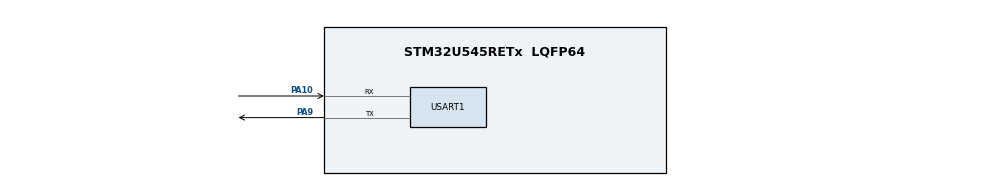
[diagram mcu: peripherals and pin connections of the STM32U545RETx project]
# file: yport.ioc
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CORTEX_M33_NS.userName=CORTEX_M33
Mcu.Family=STM32U5
Mcu.Name=STM32U545RETx
Mcu.Package=LQFP64
NVIC.PriorityGroup=NVIC_PRIORITYGROUP_4
NVIC.TIM6_IRQn=true\:15\:0\:false\:false\:true\:false\:true\:true
NVIC.TimeBase=TIM6_IRQn
NVIC.TimeBaseIP=TIM6
PA10.Mode=Asynchronous
PA10.Signal=USART1_RX
PA9.Mode=Asynchronous
PA9.Signal=USART1_TX
PC14-OSC32_IN\ (PC14).Mode=LSE-External-Oscillator
PC14-OSC32_IN\ (PC14).Signal=RCC_OSC32_IN
PC15-OSC32_OUT\ (PC15).Mode=LSE-External-Oscillator
PC15-OSC32_OUT\ (PC15).Signal=RCC_OSC32_OUT
ProjectManager.HeapSize=0x200
ProjectManager.StackSize=0x400
ProjectManager.TargetToolchain=STM32CubeIDE
RCC.ADCFreq_Value=16000000
RCC.DACCLockSelectionVirtual=RCC_DAC1CLKSOURCE_LSI
RCC.DACCLockSelectionVirtualString=RCC_DAC1CLKSOURCE_LSI
RCC.EPOD_VALUE=4000000
RCC.HSE_VALUE=16000000
RCC.HSI48_VALUE=48000000
RCC.HSI_VALUE=16000000
RCC.LSIDIV_VALUE=32000
RCC.MSI_VALUE=4000000
RCC.USBFreq_Value=48000000
RCC.VCOOutputFreq_Value=516000000
USART1.VirtualMode-Asynchronous=VM_ASYNC
VP_LPBAMQUEUE_VS_QUEUE.Mode=QUEUEMODE
VP_LPBAM_VS_SIG1.Mode=SmartRun
VP_LPBAM_VS_SIG4.Mode=LPDMA1
VP_MEMORYMAP_VS_MEMORYMAP.Mode=CurAppReg
VP_PWR_VS_SECSignals.Mode=Security/Privilege
VP_SYS_VS_tim6.Mode=TIM6
board=custom

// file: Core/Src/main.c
/* USER CODE BEGIN Header */
/**
  ******************************************************************************
  * @file           : main.c
  * @brief          : Main program body
  ******************************************************************************
  * @attention
  *
  * Copyright (c) 2024 STMicroelectronics.
  * All rights reserved.
  *
  * This software is licensed under terms that can be found in the LICENSE file
  * in the root directory of this software component.
  * If no LICENSE file comes with this software, it is provided AS-IS.
  *
  ******************************************************************************
  */
/* USER CODE END Header */
#include "main.h"

/* USER CODE BEGIN Includes */
#include "FreeRTOS.h"
#include "task.h"
/* USER CODE END Includes */

UART_HandleTypeDef huart1;

void SystemClock_Config(void);
static void MX_GPIO_Init(void);
static void MX_USART1_UART_Init(void);

/* USER CODE BEGIN 0 */
void task1(void *data){

	while(1){
		HAL_UART_Transmit(&huart1, (uint8_t *) "hello\n", 6, HAL_MAX_DELAY);
		HAL_Delay(1000);
//		vTaskDelay(pdMS_TO_TICKS(100));
	}

	vTaskDelete(NULL);
}

void task2(void *data){

	while(1){
			HAL_UART_Transmit(&huart1, (uint8_t *) "hello world from task 2\n", sizeof("hello world from task 2\n"), HAL_MAX_DELAY);
			HAL_Delay(1000);
//			vTaskDelay(pdMS_TO_TICKS(100));
		}

	vTaskDelete(NULL);

}
/* USER CODE END 0 */

int main(void)
{

  /* USER CODE BEGIN 1 */
	TaskHandle_t taskhandle1,taskhandle2;
		BaseType_t status;
  /* USER CODE END 1 */

  /* MCU Configuration--------------------------------------------------------*/

  /* Reset of all peripherals, Initializes the Flash interface and the Systick. */
  HAL_Init();

  /* Configure the system clock */
  SystemClock_Config();

  /* Initialize all configured peripherals */
  MX_GPIO_Init();
  MX_USART1_UART_Init();
  /* USER CODE BEGIN 2 */

  	status =xTaskCreate(task1, "task1", configMINIMAL_STACK_SIZE + 100 , NULL, 6, &taskhandle1);

    configASSERT(status == pdPASS);

    xTaskCreate(task2, "task2", 140, NULL, 6, &taskhandle2);

    configASSERT(status == pdPASS);

    vTaskStartScheduler();
  /* USER CODE END 2 */

  /* Infinite loop */
  while (1)
  {

  }
}

void SystemClock_Config(void)
{
  RCC_OscInitTypeDef RCC_OscInitStruct = {0};
  RCC_ClkInitTypeDef RCC_ClkInitStruct = {0};

  /** Configure the main internal regulator output voltage
  */
  if (HAL_PWREx_ControlVoltageScaling(PWR_REGULATOR_VOLTAGE_SCALE4) != HAL_OK)
  {
    Error_Handler();
  }

  /** Initializes the CPU, AHB and APB buses clocks
  */
  RCC_OscInitStruct.OscillatorType = RCC_OSCILLATORTYPE_MSI;
  RCC_OscInitStruct.MSIState = RCC_MSI_ON;
  RCC_OscInitStruct.MSICalibrationValue = RCC_MSICALIBRATION_DEFAULT;
  RCC_OscInitStruct.MSIClockRange = RCC_MSIRANGE_4;
  RCC_OscInitStruct.PLL.PLLState = RCC_PLL_NONE;
  if (HAL_RCC_OscConfig(&RCC_OscInitStruct) != HAL_OK)
  {
    Error_Handler();
  }

  /** Initializes the CPU, AHB and APB buses clocks
  */
  RCC_ClkInitStruct.ClockType = RCC_CLOCKTYPE_HCLK|RCC_CLOCKTYPE_SYSCLK
                              |RCC_CLOCKTYPE_PCLK1|RCC_CLOCKTYPE_PCLK2
                              |RCC_CLOCKTYPE_PCLK3;
  RCC_ClkInitStruct.SYSCLKSource = RCC_SYSCLKSOURCE_MSI;
  RCC_ClkInitStruct.AHBCLKDivider = RCC_SYSCLK_DIV1;
  RCC_ClkInitStruct.APB1CLKDivider = RCC_HCLK_DIV1;
  RCC_ClkInitStruct.APB2CLKDivider = RCC_HCLK_DIV1;
  RCC_ClkInitStruct.APB3CLKDivider = RCC_HCLK_DIV1;

  if (HAL_RCC_ClockConfig(&RCC_ClkInitStruct, FLASH_LATENCY_0) != HAL_OK)
  {
    Error_Handler();
  }
}

static void MX_USART1_UART_Init(void)
{

  huart1.Instance = USART1;
  huart1.Init.BaudRate = 115200;
  huart1.Init.WordLength = UART_WORDLENGTH_8B;
  huart1.Init.StopBits = UART_STOPBITS_1;
  huart1.Init.Parity = UART_PARITY_NONE;
  huart1.Init.Mode = UART_MODE_TX_RX;
  huart1.Init.HwFlowCtl = UART_HWCONTROL_NONE;
  huart1.Init.OverSampling = UART_OVERSAMPLING_16;
  huart1.Init.OneBitSampling = UART_ONE_BIT_SAMPLE_DISABLE;
  huart1.Init.ClockPrescaler = UART_PRESCALER_DIV1;
  huart1.AdvancedInit.AdvFeatureInit = UART_ADVFEATURE_NO_INIT;
  if (HAL_UART_Init(&huart1) != HAL_OK)
  {
    Error_Handler();
  }
  if (HAL_UARTEx_SetTxFifoThreshold(&huart1, UART_TXFIFO_THRESHOLD_1_8) != HAL_OK)
  {
    Error_Handler();
  }
  if (HAL_UARTEx_SetRxFifoThreshold(&huart1, UART_RXFIFO_THRESHOLD_1_8) != HAL_OK)
  {
    Error_Handler();
  }
  if (HAL_UARTEx_DisableFifoMode(&huart1) != HAL_OK)
  {
    Error_Handler();
  }

}

static void MX_GPIO_Init(void)
{

  /* GPIO Ports Clock Enable */
  __HAL_RCC_GPIOC_CLK_ENABLE();
  __HAL_RCC_GPIOA_CLK_ENABLE();

}

void HAL_TIM_PeriodElapsedCallback(TIM_HandleTypeDef *htim)
{
  if (htim->Instance == TIM6) {
    HAL_IncTick();
  }
}

void Error_Handler(void)
{
  __disable_irq();
  while (1)
  {
  }
}
